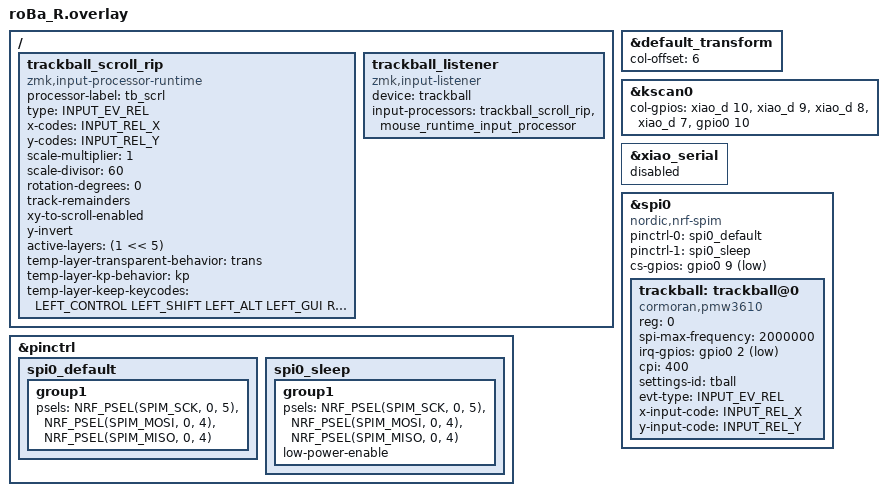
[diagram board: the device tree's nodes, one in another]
#include "roBa.dtsi"
#include <input/processors.dtsi>
#include <input/processors/runtime-input-processor.dtsi>
#include <behaviors/battery_history_request.dtsi>
#include <dt-bindings/zmk/input_transform.h>

&default_transform {
    col-offset = <6>;
};

&kscan0 {
        col-gpios
            = <&xiao_d 10 GPIO_ACTIVE_HIGH>
            , <&xiao_d 9 GPIO_ACTIVE_HIGH>
            , <&xiao_d 8 GPIO_ACTIVE_HIGH>
            , <&xiao_d 7 GPIO_ACTIVE_HIGH>
            , <&gpio0 10 GPIO_ACTIVE_HIGH>
            ;
};

/ {
    // スクロール用プロセッサ: 有効レイヤー(active-layers)の間だけXY移動をスクロールに変換する。
    // 有効レイヤー・速度・向きはDYA Studioのトラックボール画面から変更できる。
    // 他のレイヤーでは何もせず、後段のmouse_runtime_input_processorへそのまま渡す。
    trackball_scroll_rip: trackball_scroll_rip {
        compatible = "zmk,input-processor-runtime";
        processor-label = "tb_scrl"; // 最大7文字(CONFIG_ZMK_RUNTIME_INPUT_PROCESSOR_NAME_MAX_LEN=8)
        type = <INPUT_EV_REL>;
        x-codes = <INPUT_REL_X>;
        y-codes = <INPUT_REL_Y>;
        scale-multiplier = <1>;
        scale-divisor = <60>;
        rotation-degrees = <0>;
        track-remainders;
        xy-to-scroll-enabled;
        y-invert;
        active-layers = <(1 << 5)>; // 初期値: SCROLLレイヤー(5)

        temp-layer-transparent-behavior = <&trans>;
        temp-layer-kp-behavior = <&kp>;
        temp-layer-keep-keycodes = <LEFT_CONTROL LEFT_SHIFT LEFT_ALT LEFT_GUI RIGHT_CONTROL RIGHT_SHIFT RIGHT_ALT RIGHT_GUI>;

        #input-processor-cells = <0>;
    };

    trackball_listener {
        status = "okay";
        compatible = "zmk,input-listener";
        device = <&trackball>;
        // スクロール変換を先に通す(変換後はWHEEL/HWHEELになるのでmouse側は素通り)
        input-processors = <&trackball_scroll_rip &mouse_runtime_input_processor>;
    };
};

&pinctrl {
    spi0_default: spi0_default {
        group1 {
            psels = <NRF_PSEL(SPIM_SCK, 0, 5)>,
                <NRF_PSEL(SPIM_MOSI, 0, 4)>,
                <NRF_PSEL(SPIM_MISO, 0, 4)>;
        };
    };

    spi0_sleep: spi0_sleep {
        group1 {
            psels = <NRF_PSEL(SPIM_SCK, 0, 5)>,
                <NRF_PSEL(SPIM_MOSI, 0, 4)>,
                <NRF_PSEL(SPIM_MISO, 0, 4)>;
            low-power-enable;
        };
    };
};

&xiao_serial { status = "disabled"; };

&spi0 {
    status = "okay";
    compatible = "nordic,nrf-spim";
    pinctrl-0 = <&spi0_default>;
    pinctrl-1 = <&spi0_sleep>;
    pinctrl-names = "default", "sleep";
    cs-gpios = <&gpio0 9 GPIO_ACTIVE_LOW>;

    trackball: trackball@0 {
        status = "okay";
        compatible = "cormoran,pmw3610";
        reg = <0>;
        spi-max-frequency = <2000000>;
        irq-gpios = <&gpio0 2 (GPIO_ACTIVE_LOW | GPIO_PULL_UP)>;
        cpi = <400>;
        settings-id = "tball"; // DYA Studioの設定キー(cpi@tball等)。最大8文字
        evt-type = <INPUT_EV_REL>;
        x-input-code = <INPUT_REL_X>;
        y-input-code = <INPUT_REL_Y>;
    };
};
